# TC37XPD register map
Vendor: Infineon; Series: ATVMC; File version: 100
CPU: other r0p0, little endian, MPU, FPU, vendor SysTick, 4 interrupt priority bits
Registers are 32-bit, read-write, reset 0x0 unless marked. A register's access mark holds for its fields unless they carry their own. Offsets are from the block's base; [hi:lo] are bit positions; lines under a group give offsets from that group; {n}, {i} and the like mark numbered series.

## GTM (part 7 of 13)
Base 0xF0100000
0x28000 DPLL group
  0x5D0 PVT reset not defined — DPLL Plausibility Value of Next TRIGGER Slope resetvalue={PowerOn Reset:0x0,DPLL_RAM_INI.INIT_1BC:0x0}
    [23:0] PVT — Plausibility value of next active TRIGGER slope. The meaning of the value depends on the value of the PIT value in the DPLL CTRL 1 register. For PIT 0 the number of SUB INC1 pulses to be waited for until a next active TRIGGER event is accepted. For PIT 1 PVT is to be multiplied with the last nominal increment time DT T ACT and divided by 1024 and reduced to a 24 bit value in order to get the time to be waited for until the next active TRIGGER event is accepted. The wait time must be exceeded for an active slope. Note When an active TRIGGER slope is detected while the wait condition is not fulfilled the interrupt PWI is generated. Please note that the SGE1 must be set when PIT 0 in order to provide the necessary SUB INC1 pulses for checking. After an unexpected missing TRIGGER the plausibility check is suppressed for the following increment. In case of direction change the PVT value is automatically set to zero in order to deactivate the check .
  0x5E0 PSTC reset not defined — DPLL Actual Calculated Position Stamp of TRIGGER resetvalue={PowerOn Reset:0x0,DPLL_RAM_INI.INIT_1BC:0x0}
    [23:0] PSTC — Calculated position stamp of last TRIGGER input. Value is set by the DPLL and can be updated by the CPU when filter values are to be considered for the exact position see DPLL STATUS and DPLL CTRL registers for explanation of the status and control bits used . For each active slope of TRIGGER in normal mode. When FTD 0 PSTC is set from actual position value for the first active TRIGGER event no filter delay considered the CPU must update the value once taking into account the filter value. When FTD 1 PSTC is incremented at each TRIGGER event by xa0 xa0 xa0 SMC 0 MLT 1 SYN T PD while PD 0 for AMT 0 xa0 xa0 xa0 SMC 1 MLS1 SYN T PD xa0 xa0 xa0 while PD 0 for AMT 0
  0x5E4 PSSC reset not defined — DPLL Actual Calculated Position Stamp of STATE resetvalue={PowerOn Reset:0x0,DPLL_RAM_INI.INIT_1BC:0x0}
    [23:0] PSSC — Calculated position stamp for the last STATE input. First value is set by the DPLL and can be updated by the CPU when the filter delay is to be considered. For each active slope of STATE in emergency mode. When FSD 0 PSSC is set from actual position value no filter delay considered the CPU must update the value once taking into account the filter value When FSD 1 at each active slope of STATE PD S store 0 for AMS 0 160 160 160 SMC 0 add MLS1 SYN S PD S store 160 160 160 SMC 1 add MLS2 SYN S PD S store
  0x5E8 PSTM reset not defined — DPLL Measured Position Stamp at Last TRIGGER Input resetvalue={PowerOn Reset:0x0,DPLL_RAM_INI.INIT_1BC:0x0}
    [23:0] PSTM — Position stamp of TRIGGER measured. Measured position stamp of last active TRIGGER input. Store the value TBU TS1 when an active TRIGGER event occurs. The value of PSTM is invalid for RMO 1 and SMC 0 .
  0x5EC PSTM_OLD reset not defined — DPLL Measured Position Stamp at Last but One TRIGGER Input resetvalue={PowerOn Reset:0x0,DPLL_RAM_INI.INIT_1BC:0x0}
    [23:0] PSTM_OLD — Last but one position stamp of TRIGGER measured. Measured position stamp of last but one active TRIGGER input. Last PSTM value see explanation of PSTM.
  0x5F0 PSSM reset not defined — DPLL Measured Position Stamp at Last STATE Input resetvalue={PowerOn Reset:0x0,DPLL_RAM_INI.INIT_1BC:0x0}
    [23:0] PSSM — Position stamp of STATE measured. Measured position stamp of last active STATE input. Store the value TBU TS1 or TBU TS2 respectively at the moment when an active STATE event occurs. The value of PSSM is invalid for RMO 0 and SMC 0 .
  0x5F4 PSSM_OLD reset not defined — DPLL Measured Position Stamp at Last but One STATE Input resetvalue={PowerOn Reset:0x0,DPLL_RAM_INI.INIT_1BC:0x0}
    [23:0] PSSM_OLD — Last but one position stamp of STATE measured. Measured position stamp of last but one active STATE input. Last PSSM value see explanation of PSSM.
  0x5F8 NMB_T reset not defined — DPLL Number of Pulses to be Sent in Normal Mode resetvalue={PowerOn Reset:0x0,DPLL_RAM_INI.INIT_1BC:0x0}
    [15:0] NMB_T — Number of pulses for TRIGGER. Calculated number of pulses in normal mode for the current TRIGGER increment. Calculated pulse number.
  0x5FC NMB_S reset not defined — DPLL Number of Pulses to be Sent in Emergency Mode resetvalue={PowerOn Reset:0x0,DPLL_RAM_INI.INIT_1BC:0x0}
    [19:0] NMB_S — Number of pulses for STATE. Calculated number of pulses in emergency mode for the current STATE increment. Calculated pulse number.
  {0x600+4j} DPLL_RDT_Si[{j}] (j=0..63) reset not defined — DPLL Reciprocal Values of the Nominal STATE 0 Increment Duration in FULL SCALE resetvalue={PowerOn Reset:0x0,DPLL_RAM_INI.INIT_1BC:0x0}
    [23:0] RDT_S — Reciprocal difference time of STATE. Nominal reciprocal value of the number of time stamp clocks measured in the corresponding increment 2 32 while only the lower 24 bits are used no gap considered. The LSB is rounded up when the next truncated bit is 1. There are 2 SNU 1 SYN NS entries for SYSF 0 or 2 SNU 1 SYN NS entries for SYSF 1 respectively.
  {0x700+4j} DPLL_TSF_Si[{j}] (j=0..63) reset not defined — DPLL Time Stamp Values of the Nominal STATE 0 Events in FULL SCALE resetvalue={PowerOn Reset:0x0,DPLL_RAM_INI.INIT_1BC:0x0}
    [23:0] TSF_S — Time stamp field of STATE. Time stamp value of each active STATE event. There are 2 SNU 1 entries.
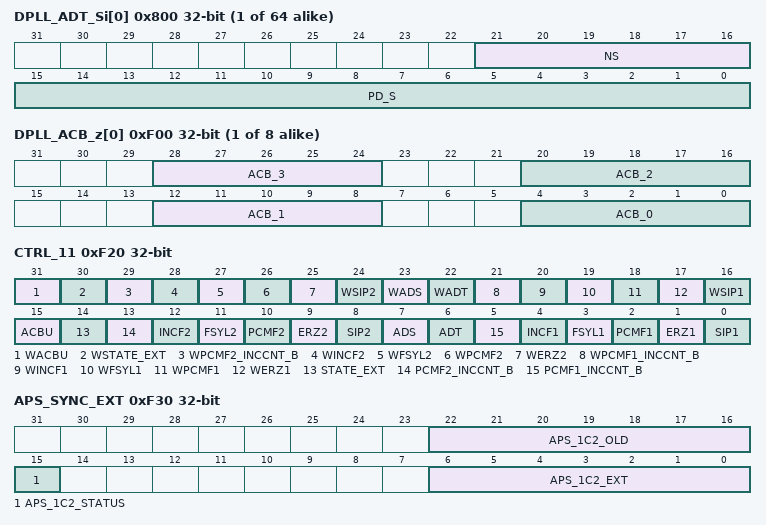
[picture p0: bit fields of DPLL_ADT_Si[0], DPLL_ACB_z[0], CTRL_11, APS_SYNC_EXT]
  {0x800+4j} DPLL_ADT_Si[{j}] (j=0..63) reset not defined — DPLL Adapt and Profile Values of the STATE 0 Increments in FULL SCALE resetvalue={PowerOn Reset:0x0,DPLL_RAM_INI.INIT_1BC:0x0}
    [21:16] NS — Number of STATEs. Number of nominal STATE parts in the corresponding increment. There are 2 SNU 1 SYN NS entries for SYSF 0 or 2 SNU 1 SYN NS entries for SYSF 1 respectively.
    [15:0] PD_S — Physical deviation of STATE. Adapt values for each STATE increment in FULL SCALE sint16 This value represents the number of pulses to be added to the correspondent nominal increment. The absolute value of a negative PD S must not exceed MLS1 or MLS2 respectively. The PD value does mean the number of SUB INC1 pulses per nominal tooth to be added to NS MLS1 2 1 PD S
  {0x900+4j} DPLL_DT_Si[{j}] (j=0..63) reset not defined — DPLL Nominal STATE 0 Increment Duration in FULL SCALE resetvalue={PowerOn Reset:0x0,DPLL_RAM_INI.INIT_1BC:0x0}
    [23:0] DT_S — Difference time of STATE. Nominal increment duration values for each STATE increment in FULL SCALE considering no gap . There are 2 SNU 1 SYN NS entries for SYSF 0 or 2 SNU 1 SYN NS entries for SYSF 1 respectively.
  {0xE00+4j} DPLL_TSACz[{j}] (j=0..31) reset 0x7FFFFF — DPLL Calculated Time Value to start Action 0 Register resetvalue={Application Reset:0x7FFFFF}
    [23:0] TSAC — Calculated time stamp for ACTION z. This value can only be written when the DPLL is disabled.
  {0xE80+4j} DPLL_PSACz[{j}] (j=0..31) reset 0x7FFFFF — DPLL ACTION Position Value Action 0 Request Register resetvalue={Application Reset:0x7FFFFF}
    [23:0] PSAC — Calculated position value for the start of ACTION z in normal or emergency mode according to equations DPLL 17 or DPLL 20 respectively. This value can only be written when the DPLL is disabled.
  {0xF00+4j} DPLL_ACB_z[{j}] (j=0..7) — DPLL Control Bits Register 0 for up to 32 Actions resetvalue={Application Reset:0x0}
    [28:24] ACB_3 — Action Control Bits of ACTION i 3 . Reflects ACT D i 3 52 48 i 4 z. When DPLL CTRL 11.ACBU 0 ACB 3 4 0 are taken as received by ARU interface and are transmitted unchanged as result of action PMT calculation. When DPLL CTRL 11.ACBU 1 ACB 3 4 2 are taken as received by ARU interface and are transmitted unchanged as result of action PMT calculation. ACB 3 1 1 is used as input signal to control if quot action in past quot shall be checked based on position information. ACB 3 1 is written to 1 if action channel has reached quot action in past quot condition after action has been calculated written to 0 if action has not reached quot past quot so far. ACB 3 0 is used as input signal to control if quot action in past quot shall be checked based on time information. ACB 3 0 is written to 1 if action channel has reached quot action in past quot condition after action has been calculated written to 0 if action has not reached quot past quot so far. This value can only be written via AEI interface when the DPLL is disabled.
    [20:16] ACB_2 — Action Control Bits of ACTION i 2 . Reflects ACT D i 2 52 48 i 4 z. When DPLL CTRL 11.ACBU 0 ACB 2 4 0 are taken as received by ARU interface and are transmitted unchanged as result of action PMT calculation. When DPLL CTRL 11.ACBU 1 ACB 2 4 2 are taken as received by ARU interface and are transmitted unchanged as result of action PMT calculation. ACB 2 1 1 is used as input signal to control if quot action in past quot shall be checked based on position information. ACB 2 1 is written to 1 if action channel has reached quot action in past quot condition after action has been calculated written to 0 if action has not reached quot past quot so far. ACB 2 0 is used as input signal to control if quot action in past quot shall be checked based on time information. ACB 2 0 is written to 1 if action channel has reached quot action in past quot condition after action has been calculated written to 0 if action has not reached quot past quot so far. This value can only be written via AEI interface when the DPLL is disabled.
    [12:8] ACB_1 — Action Control Bits of ACTION i 1 . Reflects ACT D i 1 52 48 i 4 z. When DPLL CTRL 11.ACBU 0 ACB 1 4 0 are taken as received by ARU interface and are transmitted unchanged as result of action PMT calculation. When DPLL CTRL 11.ACBU 1 ACB 1 4 2 are taken as received by ARU interface and are transmitted unchanged as result of action PMT calculation.ACB 1 1 1 is used as input signal to control if quot action in past quot shall be checked based on position information. ACB 1 1 is written to 1 if action channel has reached quot action in past quot condition after action has been calculated written to 0 if action has not reached quot past quot so far.ACB 1 0 is used as input signal to control if quot action in past quot shall be checked based on time information. ACB 1 0 is written to 1 if action channel has reached quot action in past quot condition after action has been calculated written to 0 if action has not reached quot past quot so far.This value can only be written via AEI interface when the DPLL is disabled.
    [4:0] ACB_0 — Action Control Bits of ACTION z. Reflects ACT D i 52 48 i 4 z. When DPLL CTRL 11.ACBU 0 ACB 0 4 0 are taken as received by ARU interface and are transmitted unchanged as result of action PMT calculation. When DPLL CTRL 11.ACBU 1 ACB 0 4 2 are taken as received by ARU interface and are transmitted unchanged as result of action PMT calculation. ACB 0 1 1 is used as input signal to control if quot action in past quot shall be checked based on position information. ACB 0 1 is written to 1 if action channel has reached quot action in past quot condition after action has been calculated written to 0 if action has not reached quot past quot so far. ACB 0 0 is used as input signal to control if quot action in past quot shall be checked based on time information. ACB 0 0 is written to 1 if action channel has reached quot action in past quot condition after action has been calculated written to 0 if action has not reached quot past quot so far. This value can only be written via AEI interface when the DPLL is disabled.
  0xF20 CTRL_11 access per field — DPLL Control Register 11 resetvalue={Application Reset:0x0}
    [31] WACBU rw — Write enable for ACB use. The ACB values of PMTR are used to decide whether an action is in the past. Enable writing.
    [30] WSTATE_EXT rw — Write enable of STATE EXT
    [29] WPCMF2_INCCNT_B rw — Write enable of PCMF2 INCCNT B
    [28] WINCF2 rw — Write enable for INC CNT2 fast. Enable writing.
    [27] WFSYL2 rw — Write enable for force synchronization loss 2. Enable writing.
    [26] WPCMF2 rw — Write enable for pulse correction mode fast 2. Enable writing.
    [25] WERZ2 rw — Write enable for error zero 2. Enable writing.
    [24] WSIP2 rw — Write enable for simplified increment prediction 2. Enable writing.
    [23] WADS ro — Write enable of ADS. Enable writing.
    [22] WADT ro — Write enable of ADT. Enable writing.
    [21] WPCMF1_INCCNT_B rw — Write enable of PCMF1 INCCNT B. Enable writing.
    [20] WINCF1 rw — Write enable for INC CNT1 fast. Enable writing.
    [19] WFSYL1 rw — Write enable for force synchronization loss 1. Enable writing.
    [18] WPCMF1 rw — Write enable for pulse correction mode fast 1. Enable writing.
    [17] WERZ1 rw — Write enable for error zero 1. Enable writing.
    [16] WSIP1 rw — Write enable for simplified increment prediction 1. Enable writing.
    [15] ACBU rw — ACB use the ACB values of PMTR are used to decide if an action is in the past. Return ACB values together with actions as zero when the actions are in the future Set ACB 1 1 when calculated position value is in the past and the ACB 1 of PMTR was 1. Set ACB 0 1 when calculated time value is in the past and the ACB 0 of PMTR was 1. The value of ACBU can be only written when WACBU 1.
    [14] STATE_EXT rw — Use of STATE engine extension. The STATE EXT value can be only written when WSTATE EXT 1 and the DPLL is disabled. See 18.10 for a further explanation. If this bit shall be modified during operation a software reset of the DPLL module is strongly recommended. A RAM initialisation should also be considered depending on the given application case.
    [13] PCMF2_INCCNT_B rw — No increment of INC CNT2 when PCMF2 active automatic end mode . The PCMF2 INCCNT B value can be only written when WPCMF2 INCCNT B 1.
    [12] INCF2 rw — INC CNT2 fast. The INCF2 value can be only written when WINCF2 1.
    [11] FSYL2 rw — Force Synchronization Loss of LOCK2. The synchronization loss resets SYS and prevents the use of profiles respectively. The above described effect for FSYL2 1 is only active when WFSYL2 1 simultaneously.
    [10] PCMF2 rw — Pulse correction mode fast for INC CNT2. The fast pulse generation is performed immediately within the current increment. MPVAL2 must be positive integers for the fast pulse correction mode in the case of negative values the correction is suppressed and the FPCE fast pulse correction error bit in the DPLL STATUS register is set causing the EI error interrupt when enabled. The setting of PCMF2 prevents the transfer of control bits PCM2 to the corresponding shadow registers with an active input event and therefore prevents the distribution of the MPVAL1 values over the current or next increment. The MPVAL2 pulses are sent with the fast clock CMU CLK0 by the rapid pulse generator RPCUx of specification v3.0 triggered in the state 6 26 or 18 38 of the state machines. The INC CNT2 is incremented by MPVAL2 respectively. When taken the MPVAL2 value to RPCUx and INC CNT2 the PCM2 bit is reset immediately and after that also the PCMF2 bit. The value of PCMF2 can be only written when WPCMF2 1. Be careful when using the fast pulse correction during a direction change. Because of sending the correction pulses before during or after the direction change recognition the result is typically unpredictable. No automatic correction of the fast correction pulses is provided. The necessary corrections must be performed on responsibility of the user.
    [9] ERZ2 rw — Error is assumed as zero in emergency mode and for the second engine for SMC 1. The calculation of EDT S and MEDT S is performed independently from the ERZ2 value in all modes without any influence to the MEDT S value itself. The ERZ2 value influences the use of MEDT S in emergency mode and for SMC 1 with RMO 1. The value of ERZ2 can be only written when WERZ2 1.
    [8] SIP2 rw — Simplified increment prediction in emergency mode and for the second engine in the case RMO 1. For the first increment after setting SIP2 from 0 to 1 the value of DT S ACT is replaced by the value of the DT S START register. This results in a CDT SX value which is equal to DT S START. Please notice that this DT S START value must be always gt 256. The value of SIP2 influences only the increment prediction and error accumulation when NUSE VSN 1. The calculation of QDT S itself is not influenced by the SIP2 bit. The value of SIP2 can be only written when WSIP2 1.
    [7] ADS ro — Correction of DT S ACTUAL CDT SX nom corr by PD S
    [6] ADT ro — Correction of DT T ACTUAL CDT TX nom corr by PD T
    [5] PCMF1_INCCNT_B rw — No increment of INC CNT1 when PCMF1 active automatic end mode . The PCMF1 INCCNT B value can be only written when WPCMF1 INCCNT B 1.
    [4] INCF1 rw — INC CNT1 fast correction. The calculation of ADD IN for the SUB INC generation is performed without adding the 0.5 value to NMB T S in equations DPLL 25 ff. The signal RESET SIGx of the pulse generator is activated for each new active input slope in order to reset the register values. The INCF1 value can be only written when WINCF1 1. The INCF1 bit should only be written when DPLL CTRL 1.DEN 0 DPLL disabled to prevent generation of wrong number of sub increments.
    [3] FSYL1 rw — Force Synchronization Loss of LOCK1. The synchronization loss resets SYT SYS and prevents the use of profiles respectively. The above described effect for FSYL1 1 is only active when WFSYL1 1 simultaneously.
    [2] PCMF1 rw — Pulse correction mode fast for INC CNT1. The fast pulse generation is performed immediately within the current increment. MPVAL1 must be positive integers for the fast pulse correction mode in the case of negative values the correction is suppressed and the FPCE fast pulse correction error bit in the DPLL STATUS register is set causing the EI error interrupt when enabled. The setting of PCMF1 prevents the transfer of control bits PCM1 to the corresponding shadow registers with an active input event and prevents therefore the distribution of the MPVAL1 values over the current or next increment. The MPVAL1 pulses are sent with the fast clock CMU CLK0 by the rapid pulse generator RPCUx see chapter 18.8.3.6 of specification v3.0 triggered in the state 6 26 or 18 38 of the state machines see CROSSREFERENCE respectively. The INC CNT1 is incremented by MPVAL1 respectively. When taken the MPVAL1 value to RPCUx and INC CNT1 the PCM1 bit is reset immediately and after that also the PCMF1 bit. The value of PCMF1 can be only written when WPCMF1 1. Be careful when using the fast pulse correction during a direction change. Because of sending the correction pulses before during or after the direction change recognition the result is typically unpredictable. No automatic correction of the fast correction pulses is provided. The necessary corrections must be performed on responsibility of the user.
    [1] ERZ1 rw — Error is assumed as zero in normal mode and for the first engine for SMC 1. The calculation of EDT T and MEDT T is performed independently from the ERZ1 value in all modes without any influence to the MEDT T value itself. The ERZ1 value influences the use of MEDT T in normal mode and for SMC 1. The value of ERZ1 can be only written when WERZ1 1.
    [0] SIP1 rw — Simplified increment prediction in normal mode and for the first engine in the case SMC 1. For the first increment after setting SIP1 from 0 to 1 the value of DT T ACT is replaced by the value of the DT T START register. This results in a CDT TX value which is equal to DT T START. Please notice that this DT T Start value must be always gt 256. The value of SIP1 influences only the increment prediction CDT TX and when NUTE VTN 1. The calculation of QDT T itself is not influenced by the SIP1 bit. The value of SIP1 can be only be written when WSIP1 1. When SIP1 1 is set the first pulses of the subincrement generator are not generated with highest frequency for the first increment DPLL STATUS.FTD 0 DPLL CTRL 1.SGE1 1 .
  0xF24 THVAL2 ro — DPLL Immediate THVAL Value Register resetvalue={Application Reset:0x0}
    [23:0] THVAL — Measured last pulse time from active to inactive slope of TRIGGER after correction of input slope filter delays. This value is available immediately after the inactive slope of TRIGGER. The measured value considers all input slope filter delays. From the received input the corresponding filter delays are subtracted before the time stamp difference of active and inactive slope is calculated.
  0xF28 TIDEL — DPLL Additional TRIGGER Input Delay Register resetvalue={Application Reset:0x0}
    [23:0] TIDEL — TRIGGER input delay. Transmit this value with each active TRIGGER slope into a shadow register. Subtract this shadow register value from each TRIGGER time stamp active and inactive slope . This feature is always active and cannot be disabled by a control bit.
  0xF2C SIDEL — DPLL Additional STATE Input Delay Register resetvalue={Application Reset:0x0}
    [23:0] SIDEL — STATE input delay. Transmit this value with each active STATE slope into a shadow register. Subtract this shadow register value from each STATE time stamp active and inactive slope . This feature is always active and cannot be disabled by a control bit.
  0xF30 APS_SYNC_EXT — DPLL Extension Register for DPLL APS SYNC resetvalue={Application Reset:0x0}
    [22:16] APS_1C2_OLD — Address pointer STATE for RAM region 1c2 at synchronization time. This value is set by the current APS 1C2 value when the synchronization takes place for the first active STATE event after writing APS 1C3 but before adding the offset value APS 1C2 EXT that means when APS 1C2 STATUS 1 . Address pointer APS 1C2 value at the moment of synchronization before the offset value is added that means the pointer with this value points to the last value before the additional inserted gap.
    [15] APS_1C2_STATUS — Address pointer 1c2 status. Set by CPU before the synchronization is performed. The value is cleared automatically when the APS 1C2 OLD value is written.
    [6:0] APS_1C2_EXT — Address pointer 1c2 extension. This offset value determines by which value the APS 1C2 is changed at the synchronization time set by CPU before the synchronization is performed. This offset value is the number of virtual increments to be inserted in the TSF for an imminent intended synchronization the CPU sets its value dependent on the gaps until the synchronization time taking into account the considered NUSE value to be set and including the next future increment when SYN S OLD is still 1 . When the synchronization takes place this value is to be added to the APS 1C2 address pointer for forward direction DIR2 0 and the APT 1c2 status bit is cleared after it. For backward direction subtract APS 1C2 EXT accordingly. When the synchronization is intended and the NUSE value is to be set to FULL SCALE after it the APS 1C2 EXT value must be set to SYN NS for SYSF 1 or 2 SYN NS for SYSF 0 in order to be able to fill all gaps in the extended TSF S with the corresponding values by the CPU. When still not all values for FULL SCALE are available the APS 1C2 EXT value considers only a share according to the NUSE value to be set after the synchronization.
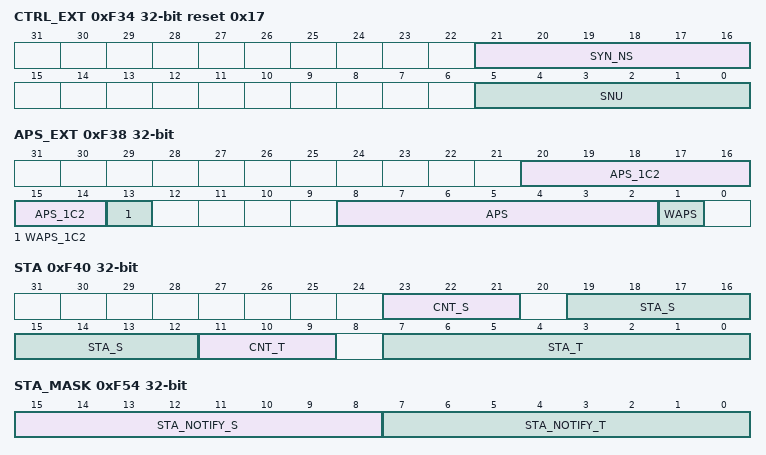
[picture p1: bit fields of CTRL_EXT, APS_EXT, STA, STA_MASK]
  0xF34 CTRL_EXT reset 0x17 — DPLL Extension Register for DPLL CTRL resetvalue={Application Reset:0x17}
    [21:16] SYN_NS — Synchronization number of STATE. Summarized number of virtual increments in HALF SCALE. Sum of all systematic missing STATE events in HALF SCALE for SYSF 0 or FULL SCALE for SYSF 1 the SYN NS missing STATES can be divided up to an arbitrary number of blocks. The pattern of events and missing events in FULL SCALE is shown in RAM region 1c3 as value NS in addition to the adapted values. The number of stored increments in FULL SCALE must be equal to 2 SNU 1 SYN NS for SYSF 0 or 2 SNU 1 SYN NS for SYSF 1 . This pattern is written by the CPU beginning from a fixed reference point maybe beginning of the FULL SCALE region . The relation to the actual increment is established by setting of the profile RAM pointer APS 1C3 in an appropriate relation to the RAM pointer APS of the actual increment by the CPU. This value can only be written when the DPLL is disabled. This value can only be written when RMO 0 and SMC 0 or DEN 0. Set SSL 00 before changing this value and set RMO 1 only after FULL SCALE with SSL gt 0.
    [5:0] SNU — STATE number. This bit can only be written when the DPLL is disabled. The number of nominal STATE events is the decimal value plus 1. This value can only be written when RMO 0 and SMC 0 or DEN 0. Set SSL 00 before changing this value and set RMO 1 only after FULL SCALE with SSL gt 0.
  0xF38 APS_EXT — DPLL Extension Register for DPLL APS resetvalue={Application Reset:0x0}
    [20:14] APS_1C2 — Actual RAM pointer address value for TSF S i . Initial value zero 0x00 . Actual RAM pointer and synchronization position value of STATE events in FULL SCALE for up to 64 STATE events but limited to 2 SNU 1 in normal and emergency mode this pointer is used for the RAM region 1c2. For SYS 1 APS 1C2 is incremented decremented by SYN S OLD for each active STATE event and DIR2 0 DIR2 1 . For SYS 0 APT 1c2 is incremented or decremented by 1 respectively. The APS 1C2 offset value is added in the above shown bit position with the subsection offset of the RAM region. In addition when the APS 1C3 value is written by the CPU in order to synchronize the DPLL with the next active STATE event the APS 1C2 EXT value is added subtracted while APS 1C2 STATUS is one see DPLL APT SYNC register at CROSSREFERENCE . This value can only be written when the WAPS 1C2 bit is set
    [13] WAPS_1C2 — Write bit for address pointer APS 1C2. Read as zero.
    [8:2] APS — Actual RAM pointer address value for DT S i and RDT S i . Actual RAM pointer and synchronization position value of STATE events in FULL SCALE for up to 128 STATE events but limited to 2 SNU 1 SYN NS in normal and emergency mode for SYSF 0 or to 2 SNU 1 SYN NS for SYSF 1 respectively See CROSSREFERENCE . APS is incremented decremented by one for each active STATE event and DIR2 0 DIR2 1 . The APS offset value is added in the above shown bit position with the subsection offset of the RAM region. The APS pointer value is directed to the RAM position in which the data values are to be written which correspond to the last increment. The APS value is not to be changed when the direction shown by DIR2 changes because it points always to a storage place after the considered increment. Changing of DIR2 takes place always after an active STATE event and the resulting increment decrement. This value can only be written when the WAPS bit is set.
    [1] WAPS — Write bit for address pointer APS. Read as zero.
  0xF3C APS_1C3_EXT — DPLL Extension Register for DPLL APS 1C3 resetvalue={Application Reset:0x0}
    [8:2] APS_1C3 — Actual RAM pointer address value for ADT S i . Initial value zero 0x00 . Actual RAM pointer and synchronization position value of STATE events in FULL SCALE for up to 128 STATE events but limited to 2 SNU 1 SYN NS in normal and emergency mode for SYSF 0 or to 2 SNU 1 SYN NS for SYSF 1 respectively this pointer is used for the RAM region 1c3. See CROSSREFERENCE . The RAM pointer is set by the CPU accordingly when the synchronization condition was detected. The APS 1C3 pointer value is directed to the RAM position of the profile element in RAM region 1c2 which corresponds to the current increment. When changing the direction DIR1 or DIR2 respectively this is always known before an active STATE event is processed. This is because of the pattern recognition in SPE for PMSM or because of the direction change recognition by TRIGGER. This direction change results in an automatic increment forwards or decrement backwards when the input event occurs in addition with a 2 times correction. The APS 1C3 x offset value is added in the above shown bit position with the subsection address offset of the corresponding RAM region.
  0xF40 STA ro — DPLL Status of the State Machine States Register resetvalue={Application Reset:0x0}
    [23:21] CNT_S — Count STATE. This reflects the count of active STATE slopes mod8 . This value shows the number of active STATE slopes mod8 . This value allows distinguishing if the above state machine status is consistent to other status values read before or after it.
    [19:12] STA_S — Status of STATE state machine. State binary coded. This bit field reflects the status of the STATE state machine. The decimal step number 21 to 40 of the state machine is binary coded from 0x01 to 0x14 respectively using the upper 5 bits 20 16 after subtraction of 20 to the decimal value. The lower 4 bits 15 12 show substates of the corresponding state machine. When the DPLL is disabled this field is 0x000. Table STA S
    [11:9] CNT_T — Count TRIGGER. This reflects the count of active TRIGGER slopes mod8 . This value shows the number of active TRIGGER slopes mod8 . This value allows distinguishing if the above state machine status is consistent to other status values read before or after it.
    [7:0] STA_T — Status of TRIGGER state machine state binary coded. This bit field reflects the status of the TRIGGER state machine. The decimal step number 1 to 20 of the state machine is binary coded from 0x01 to 0x14 respectively using the upper 5 bits 8 4 . The lower 4 bits 3 0 show substates of the corresponding state machine. When the DPLL is disabled this field is 0x000. Table STA T
  0xF44 INCF1_OFFSET — DPLL Start Value of the ADD IN ADDER1 Register resetvalue={Application Reset:0x0}
    [23:0] DPLL_INCF1_OFFSET — Start value of the ADD IN ADDER1. In the case of set DPLL CTRL 11 INCF1 the ADD IN ADDER1 starts always after an active new input event TRIGGER in normal mode or STATE in emergency mode respectively with this offset value. In the case of choosing DPLL INCF1 OFFSET 0xFFFFFF the generation of the first SUB INC1 pulse is performed with the next TS CLK. In the case of DPLL INCF1 OFFSET 0x000000 the first pulse is delayed by a full SUB INC1 period and in the case of DPLL INCF1 OFFSET 0x7FFFFF the first pulse is delayed by a half SUB INC1 period. Any other value is possible.
  0xF48 INCF2_OFFSET — DPLL Start Value of the ADD IN ADDER2 Register resetvalue={Application Reset:0x0}
    [23:0] DPLL_INCF2_OFFSET — Start value of the ADD IN ADDER2. In the case of set DPLL CTRL 11 INCF2 the ADD IN ADDER2 starts always after an active new input event STATE with this offset value. In the case of choosing DPLL INCF2 OFFSET 0xFFFFFF the generation of the first SUB INC2 pulse is performed with the next TS CLK. In the case of DPLL INCF2 OFFSET 0x000000 the first pulse is delayed by a full SUB INC2 period and in the case of DPLL INCF2 OFFSET 0x7FFFFF the first pulse is delayed by a half SUB INC2 period. Any other value is possible.
  0xF4C DT_T_START reset 0x101 — DPLL Start Value of DPLL DT T ACT for the First Increment after SIP1 is Set to 1 resetvalue={Application Reset:0x101}
    [23:0] DPLL_DT_T_START — Start value of DPLL DT T ACT for the first increment after SIP1 is set to 1. For the first increment after setting SIP1 from 0 to 1 the value of DPLL DT T START is taken instead of the calculated DPLL DT T ACT for the current increment duration. This value should be always gt 256 in order to avoid an overflow during the calculation of DPLL RDT T ACT.
  0xF50 DT_S_START reset 0x101 — DPLL Start Value of DPLL DT S ACT for the First Increment after SIP2 is Set to 1 resetvalue={Application Reset:0x101}
    [23:0] DPLL_DT_S_START — Start value of DPLL DT S ACT for the first increment after SIP2 is set to 1. For the first increment after setting SIP2 from 0 to 1 the value of DPLL DT S START is taken instead of the calculated DPLL DT S ACT for the current increment duration. This value should be always gt 256 in order to avoid an overflow during the calculation of DPLL RDT S ACT.
  0xF54 STA_MASK — DPLL Trigger Masks for Signals DPLL STA T and DPLL STA S resetvalue={Application Reset:0x0}
    [15:8] STA_NOTIFY_S — Notify value for STA S of register DPLL STA. The STA NOTIFY S is representing a trigger mask of DPLL STA.STA S. When DPLL STA.STA S reaches the value of STA NOTIFY S the flag DPLL STA FLAG.STA FLAG S is set to 1 when DPLL STA.STA S is leaving the state STA NOTIFY S.
    [7:0] STA_NOTIFY_T — Notify value for STA T of register DPLL STA. The STA NOTIFY T is representing a trigger mask of DPLL STA.STA T. When DPLL STA.STA T reaches the value of STA NOTIFY T the flag DPLL STA FLAG.STA FLAG T is set to 1 when DPLL STA.STA T is leaving the state STA NOTIFY T.The signal is visible to MCS0 sub module as part of the special function register.
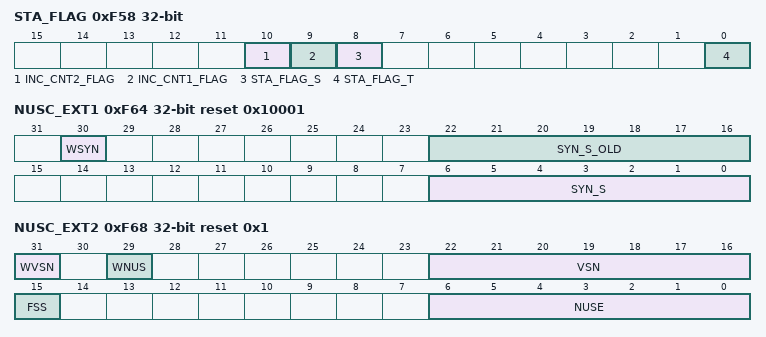
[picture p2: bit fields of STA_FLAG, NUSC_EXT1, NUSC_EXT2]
  0xF58 STA_FLAG — DPLL STA Flag Register resetvalue={Application Reset:0x0}
    [10] INC_CNT2_FLAG — Flag according to DPLL INC CNT2 MASK.INC CNT2 NOTIFY. The INC CNT2 FLAG is set to 1 indicating that the signal DPLL INC CNT2.INC CNT2 has left the state defined by the trigger mask of DPLL INC CNT2 MASK.INC CNT2 NOTIFY. The Flag is reset when this bit of the register is written to 1 . The signal is visible to MCS0 sub module as part of the special function register.
    [9] INC_CNT1_FLAG — Flag according to DPLL INC CNT1 MASK.INC CNT1 NOTIFY. The INC CNT1 FLAG is set to 1 indicating that the signal DPLL INC CNT1.INC CNT1 has left the state defined by the trigger mask of DPLL INC CNT1 MASK.INC CNT1 NOTIFY. The Flag is reset when this bit of the register is written to 1 . The signal is visible to MCS0 sub module as part of the special function register.
    [8] STA_FLAG_S — Flag according to DPLL STA MASK.STA NOTIFY S. The STA FLAG S is set to 1 indicating that the signal DPLL STA.STA S has left the state defined by the trigger mask of DPLL STA MASK.STA NOTIFY S. The Flag is reset when this bit of the register is written to 1 . The signal is visible to MCS0 sub module as part of the special function register.
    [0] STA_FLAG_T — Flag according to DPLL MASK.STA NOTIFY T. The STA FLAG T is set to 1 indicating that the signal DPLL STA.STA T has left the state defined by the trigger mask of DPLL STA MASK.STA NOTIFY T. The Flag is reset when this bit of the register is written to 1 . The signal is visible to MCS0 sub module as part of the special function register.
  0xF5C INC_CNT1_MASK — DPLL INC CNT1 Trigger Mask resetvalue={Application Reset:0x0}
    [23:0] INC_CNT1_NOTIFY — Notify value for INC CNT1 of register DPLL INC CNT1. The INC CNT1 NOTIFY is representing a trigger mask of DPLL INC CNT1.INC CNT1. When DPLL INC CNT1.INC CNT1 reaches the value of INC CNT1 NOTIFY the flag DPLL STA FLAG.INC CNT1 FLAG is set to 1 when DPLL INC CNT1.INC CNT1 is leaving the state INC CNT1 NOTIFY.
  0xF60 INC_CNT2_MASK — DPLL INC CNT2 Trigger Mask resetvalue={Application Reset:0x0}
    [23:0] INC_CNT2_NOTIFY — Notify value for INC CNT2 of register DPLL INC CNT2. The INC CNT2 NOTIFY is representing a trigger mask of DPLL INC CNT2.INC CNT2. When DPLL INC CNT2.INC CNT2 reaches the value of INC CNT2 NOTIFY the flag DPLL STA FLAG.INC CNT2 FLAG is set to 1 when DPLL INC CNT2.INC CNT2 is leaving the state INC CNT2 NOTIFY.
  0xF64 NUSC_EXT1 reset 0x10001 — DPLL Extension Register Number 1 for DPLL NUSC 4 resetvalue={Application Reset:0x10001}
    [30] WSYN — Write control bit for SYN S and SYN S OLD. Read as zero.
    [22:16] SYN_S_OLD — Number of real and virtual events to be considered for the last increment. This value reflects the NS value of the last but one valid increment stored in ADT S i is updated automatically when writing SYN S. This value is updated by the SYN S value when the WSYN bit in this register is set.
    [6:0] SYN_S — Number of real and virtual events to be considered for the current increment. This value reflects the NS value of the last valid increment stored in ADT S i to be updated after all calculations in step 37 of Table CROSSREFERENCE . This value can only be written when the WSYN bit in this register is set.
  0xF68 NUSC_EXT2 reset 0x1 — DPLL Extension Register Number 2 for DPLL NUSC 4 resetvalue={Application Reset:0x1}
    [31] WVSN — Write control bit for VSN. Read as zero.
    [29] WNUS — Write control bit for NUSE. Read as zero.
    [22:16] VSN — Number of virtual state increments in the current NUSE region. This value reflects the number of virtual increments in the current NUSE region for NUSE 1 this value is zero when the CPU sets NUSE to a value gt 1 or zero 2 7 modulo 2 7 it must also set VSN to the correspondent value the VSN value is subtracted from the NUSE value in order to get the corresponding APS value for the past the VSN value is not used for the APS 1C2 pointer. VSN is to be updated by the CPU when a new gap is to be considered for NUSE or a gap is leaving the NUSE region for this purpose the SASI interrupt can be used no further update of VSN is necessary when NUSE is set to FULL SCALE. This value can only be written when the WVSN bit is set.
    [15] FSS — This value is to be set when NUSE is set to FULL SCALE. This value is set by the CPU but reset automatically to 0 by a change of direction or loss of LOCK. This value can only be written when the WNUS bit is set.
    [6:0] NUSE — Number of recent STATE events used for SUB INCx calculations modulo 2 SNUmax 1 . No gap is considered in that case for this value but in the VSN value see below This register is set by the CPU but reset automatically to 8220 1 8221 by a change of direction or loss of LOCK. Each other value can be set by the CPU maybe Full SCALE HALF SCALE or parts of them. The relation values QDT Sx are calculated using NUSE values in the past with its maximum value of 2 SNU 1. This value can only be written when the WNUS bit is set.
  0xF6C CTN_MIN — DPLL Minimum CDT T Nominal Value Register resetvalue={Application Reset:0x0}
    [23:0] CTN_MIN — CDT T NOM min value. Use this register value as CDT T NOM value when the calculated value for the nominal increment prediction of TRIGGER is less than the register value.
  0xF70 CTN_MAX reset 0xFFFFFF — DPLL Maximum CDT T Nominal Value Register resetvalue={Application Reset:0x0FFFFFF}
    [23:0] CTN_MAX — CDT T NOM max value. Use this register value as CDT T NOM value when the calculated value for the nominal increment prediction of TRIGGER is greater than the register value.
  0xF74 CSN_MIN — DPLL Minimum CDT S Nominal Value Register resetvalue={Application Reset:0x0}
    [23:0] CSN_MIN — CDT SX NOM min value . Use this register value as CDT SX NOM value when the calculated value for the nominal increment prediction of STATE is less than the register value.
  0xF78 CSN_MAX reset 0xFFFFFF — DPLL Maximum CDT S Nominal Value Register resetvalue={Application Reset:0x0FFFFFF}
    [23:0] CSN_MAX — CDT SX NOM max value. Use this register value as CDT SX NOM value when the calculated value for the nominal increment prediction of STATE is greater than the register value.
